VERSION "synthetic-public-1"
NS_ :

BS_:
BU_: Simulator Meter
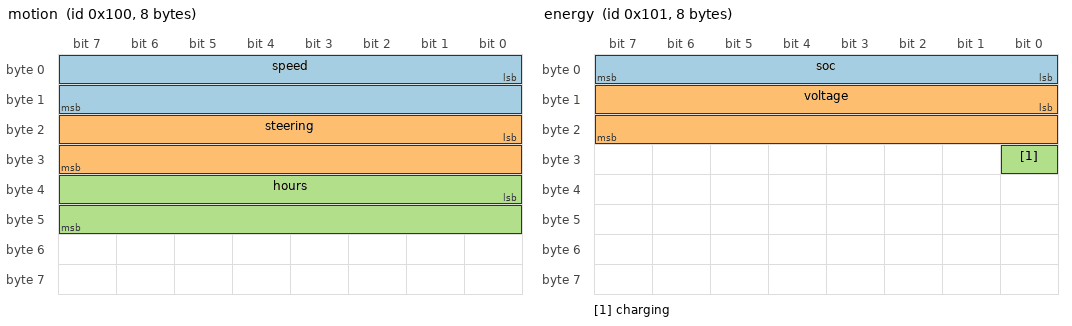
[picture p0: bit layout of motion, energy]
BO_ 256 motion: 8 Simulator
 SG_ speed : 0|16@1+ (0.01,0) [0|50] "km/h" Meter
 SG_ steering : 16|16@1- (0.01,0) [-45|45] "deg" Meter
 SG_ hours : 32|16@1+ (0.1,0) [0|6553.5] "h" Meter
BO_ 257 energy: 8 Simulator
 SG_ soc : 0|8@1+ (1,0) [0|100] "%" Meter
 SG_ voltage : 8|16@1+ (0.01,0) [0|100] "V" Meter
 SG_ charging : 24|1@1+ (1,0) [0|1] "" Meter
BO_ 258 lift: 8 Simulator
 SG_ height : 0|16@1+ (0.001,0) [0|6] "m" Meter
BO_ 259 load: 8 Simulator
 SG_ weight : 0|16@1+ (1,0) [0|1500] "kg" Meter
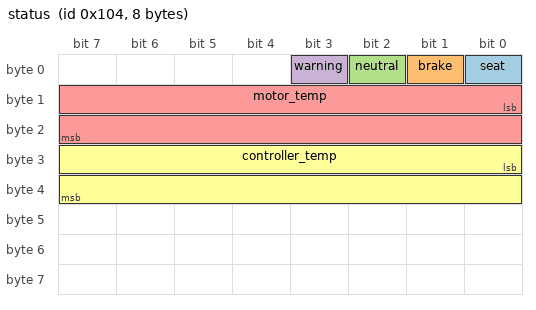
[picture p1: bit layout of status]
BO_ 260 status: 8 Simulator
 SG_ seat : 0|1@1+ (1,0) [0|1] "" Meter
 SG_ brake : 1|1@1+ (1,0) [0|1] "" Meter
 SG_ neutral : 2|1@1+ (1,0) [0|1] "" Meter
 SG_ warning : 3|1@1+ (1,0) [0|1] "" Meter
 SG_ motor_temp : 8|16@1- (1,0) [-40|150] "C" Meter
 SG_ controller_temp : 24|16@1- (1,0) [-40|150] "C" Meter
